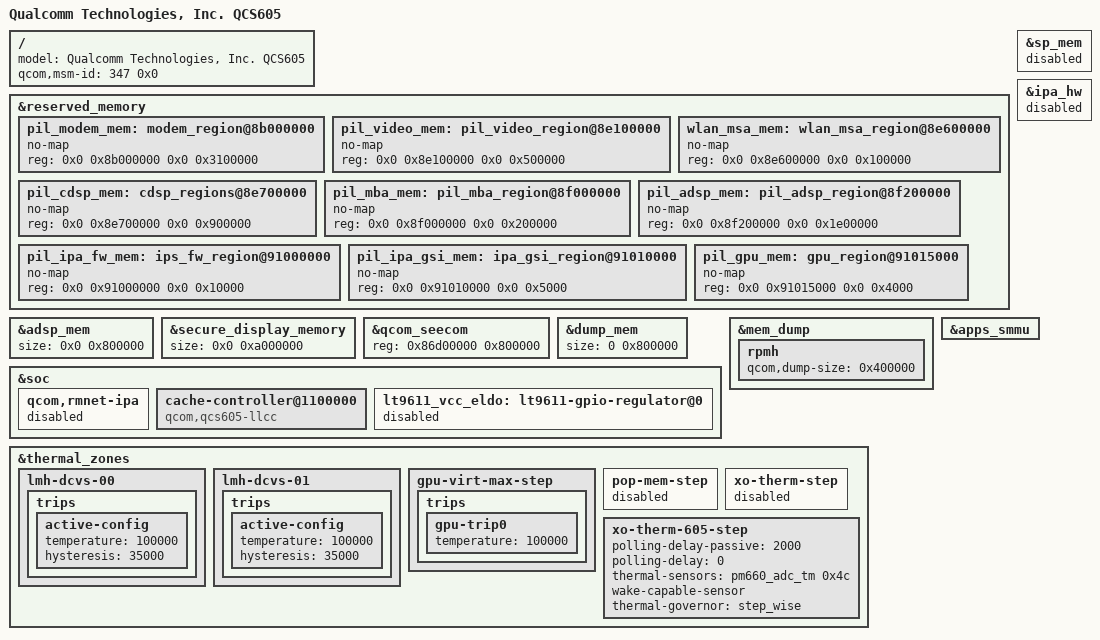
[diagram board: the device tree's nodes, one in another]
#include "sda670.dtsi"

/ {
	model = "Qualcomm Technologies, Inc. QCS605";
	qcom,msm-id = <347 0x0>;
};

&reserved_memory {
	/delete-node/ modem_region@8b000000;
	/delete-node/ pil_video_region@92e00000;
	/delete-node/ wlan_msa_region@93300000;
	/delete-node/ cdsp_regions@93400000;
	/delete-node/ pil_mba_region@0x93c00000;
	/delete-node/ pil_adsp_region@93e00000;
	/delete-node/ ips_fw_region@0x95c00000;
	/delete-node/ ipa_gsi_region@0x95c10000;
	/delete-node/ gpu_region@0x95c15000;

	pil_modem_mem: modem_region@8b000000 {
		no-map;
		reg = <0x0 0x8b000000 0x0 0x3100000>;
	};

	pil_video_mem: pil_video_region@8e100000 {
		no-map;
		reg = <0x0 0x8e100000 0x0 0x500000>;
	};

	wlan_msa_mem: wlan_msa_region@8e600000 {
		no-map;
		reg = <0x0 0x8e600000 0x0 0x100000>;
	};

	pil_cdsp_mem: cdsp_regions@8e700000 {
		no-map;
		reg = <0x0 0x8e700000 0x0 0x900000>;
	};

	pil_mba_mem: pil_mba_region@8f000000 {
		no-map;
		reg = <0x0 0x8f000000 0x0 0x200000>;
	};

	pil_adsp_mem: pil_adsp_region@8f200000 {
		no-map;
		reg = <0x0 0x8f200000 0x0 0x1e00000>;
	};

	pil_ipa_fw_mem: ips_fw_region@91000000 {
		no-map;
		reg = <0x0 0x91000000 0x0 0x10000>;
	};

	pil_ipa_gsi_mem: ipa_gsi_region@91010000 {
		no-map;
		reg = <0x0 0x91010000 0x0 0x5000>;
	};

	pil_gpu_mem: gpu_region@91015000 {
		no-map;
		reg = <0x0 0x91015000 0x0 0x4000>;
	};
};

&adsp_mem {
	size = <0x0 0x800000>;
};

&secure_display_memory {
	size = <0x0 0xa000000>;
};

&qcom_seecom {
	reg = <0x86d00000 0x800000>;
	/delete-property/ qcom,appsbl-qseecom-support;
};

&sp_mem {
	status = "disabled";
};

&dump_mem {
	size = <0 0x800000>;
};

&soc {
	qcom,rmnet-ipa {
		status = "disabled";
	};

	cache-controller@1100000 {
		/delete-property/ compatible;
		compatible = "qcom,qcs605-llcc";
	};

	lt9611_vcc_eldo: lt9611-gpio-regulator@0 {
		status = "disabled";
	};
};

&ipa_hw {
	status = "disabled";
};

&mem_dump {
	rpmh {
		qcom,dump-size = <0x400000>;
	};
};

&thermal_zones {
	lmh-dcvs-00 {
		trips {
			active-config {
				temperature = <100000>;
				hysteresis = <35000>;
			};
		};
	};

	lmh-dcvs-01 {
		trips {
			active-config {
				temperature = <100000>;
				hysteresis = <35000>;
			};
		};
	};

	gpu-virt-max-step {
		trips {
			gpu-trip0 {
				temperature = <100000>;
			};
		};
	};

	pop-mem-step {
		status = "disabled";
	};

	xo-therm-step {
		status = "disabled";
	};

	xo-therm-605-step {
		polling-delay-passive = <2000>;
		polling-delay = <0>;
		thermal-sensors = <&pm660_adc_tm 0x4c>;
		wake-capable-sensor;
		thermal-governor = "step_wise";
		status = "ok";
	};
};

&apps_smmu {
	/delete-property/ qcom,actlr;
};
